# T113-S3 register map
Vendor: Allwinner; Series: T113-S3; File version: 0.1
CPU: other 0, little endian, MPU, no FPU, 0 interrupt priority bits
Registers are 32-bit, read-write, reset 0x0 unless marked. A register's access mark holds for its fields unless they carry their own. Offsets are from the block's base; lines under a group give offsets from that group; [hi:lo] are bit positions; {n}, {i} and the like mark numbered series; 'fields as' and 'values as' point back to an identical list; <NAME> marks a mode.

## Memory map
0x01701000 DSP_MSGBOX
0x02000000 GPIO
0x02000C00 PWM
0x02001000 CCU
0x02003000 CIR_TX
0x02008000 LEDC
0x02009000 GPADC
0x02009400 THS
0x02009C00 TPADC
0x02010000 IOMMU
0x02030000 Audio_Codec
0x02031000 DMIC
0x02033000 I2S/PCM1
0x02034000 I2S/PCM2
0x02036000 OWA
0x02050000 Timer
0x02500000 UART0
0x02500400 UART1
0x02500800 UART2
0x02500C00 UART3
0x02501000 UART4
0x02501400 UART5
0x02502000 TWI0
0x02502400 TWI1
0x02502800 TWI2
0x02502C00 TWI3
0x02504000 CAN0
0x02504400 CAN1
0x03000000 SYS_CFG
0x03002000 DMAC
0x03003000 ARM_CPUX_MSGBOX
0x03005000 Spinlock
0x03008000 HSTimer
0x03040000 CE_NS_(Non-Security_CE)
0x03040800 CE_S_(Security_CE)
0x04020000 SMHC0
0x04021000 SMHC1
0x04022000 SMHC2
0x04026000 SPI_DBI
0x04200000 USB1
0x04500000 EMAC
0x05461000 TCON_LCD0
0x05470000 TCON_TV0
0x05600000 TVE_TOP
0x05604000 TVE
0x05800000 CSIC_CCU
0x05800800 CSIC_TOP
0x05801000 CSIC_PARSER0
0x05809000 CSIC_DMA0
0x05809200 CSIC_DMA1
0x05C00000 TVD_TOP
0x05C01000 TVD0
0x07040000 CIR_RX
0x07090000 RTC
0x08100000 CPU_SUBSYS_CTRL
0x09010000 C0_CPUX_CFG

## CPU_SUBSYS_CTRL
Base 0x08100000
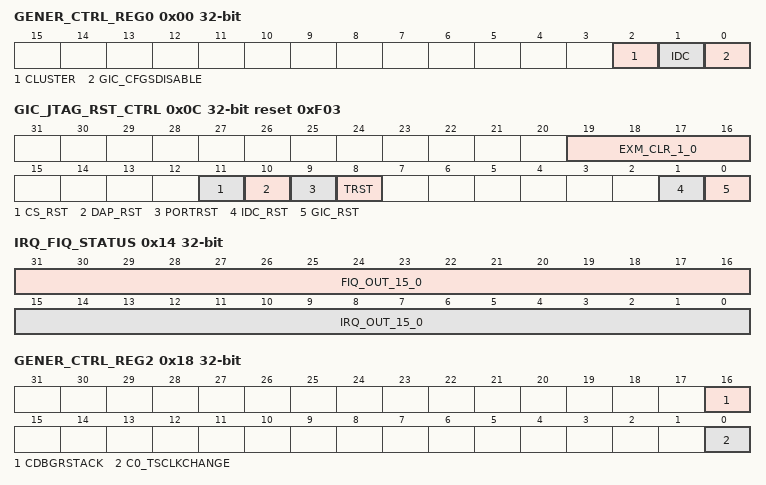
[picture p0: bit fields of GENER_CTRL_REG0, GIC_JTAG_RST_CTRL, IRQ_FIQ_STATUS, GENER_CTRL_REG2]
0x00 GENER_CTRL_REG0 — General Control Register0
  [2] CLUSTER — Cluster 0 Corepll Select Register width state 0: CCU clock 1: Disp PLL clock
    0=CCU (CCU clock); 1=Disp PLL clock
  [1] IDC — Clock Enable 0: IDC clock is disabled 1: IDC clock is enabled
    0=disabled (IDC clock is disabled); 1=enabled (IDC clock is enabled)
  [0] GIC_CFGSDISABLE — Disable write access to some secure GIC registers. 0: Write access to some secure GIC registers is enabled. 1: Write access to some secure GIC registers is disabled.
    0=enabled (Write access to some secure GIC registers is enabled.); 1=disabled (Write access to some secure GIC registers is disabled.)
0x0C GIC_JTAG_RST_CTRL reset 0xF03 — GIC and JTAG Reset Control Register
  [19:16] EXM_CLR_1_0 — EXM_CLR[1:0] (The bit[19:18] is not used) Clear the status of interface for debug.
  [11] CS_RST — CoreSight reset 0: Assert 1: De-assert
    0=Assert; 1=deassert
  [10] DAP_RST — DAP reset 0: Assert 1: De-assert
    0=Assert; 1=deassert
  [9] PORTRST — DAP reset signal control 0: Assert 1: De-assert
    0=Assert; 1=deassert
  [8] TRST — JTAG RTST signal 0: Assert 1: De-assert
    0=Assert; 1=deassert
  [1] IDC_RST — Interrupt delay controller reset 0: Assert 1: De-assert
    0=Assert; 1=deassert
  [0] GIC_RST — GIC_reset_cpu_reg 0: Assert 1: De-assert
    0=Assert; 1=deassert
0x10 C0_INT_EN reset 0xFFFF — Cluster0 Interrupt Enable Control Register
  [15:0] C0_GIC_EN — Mask the FIQ_OUT[15:0] and IRQ_OUT[15:0] signals to system domain. The meaning of each bit: 0: Mask the FIQ_OUT and IRQ_OUT signals to system domain. 1: Not to mask the FIQ_OUT and IRQ_OUT signals to system domain.
0x14 IRQ_FIQ_STATUS
  [31:16] FIQ_OUT_15_0, [15:0] IRQ_OUT_15_0
0x18 GENER_CTRL_REG2 — General Control Register2
  [16] CDBGRSTACK — Debug Reset ACK 0: There are no debug reset ACKs. 1: There are debug reset ACKs.
    0=There are no debug reset ACKs; 1=There are debug reset ACKs
  [0] C0_TSCLKCHANGE — Cluster 0 time stamp change. 0: There are no time stamp changes. 1: There are time stamp changes.
    0=There are no time stamp changes; 1=There are time stamp changes
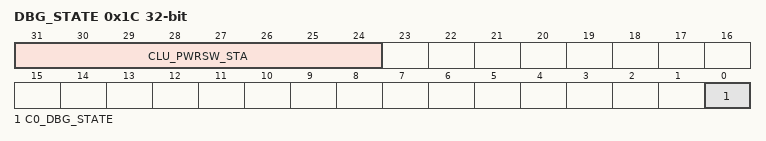
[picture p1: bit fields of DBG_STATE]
0x1C DBG_STATE — Debug State Register
  [31:24] CLU_PWRSW_STA ro
  [0] C0_DBG_STATE ro — Indicates if Cluster0 is in debug mode or normal mode. 0: Normal mode 1: Debug mode
    0=Normal_mode; 1=Debug_mode

## Licence text in the file
questionable
